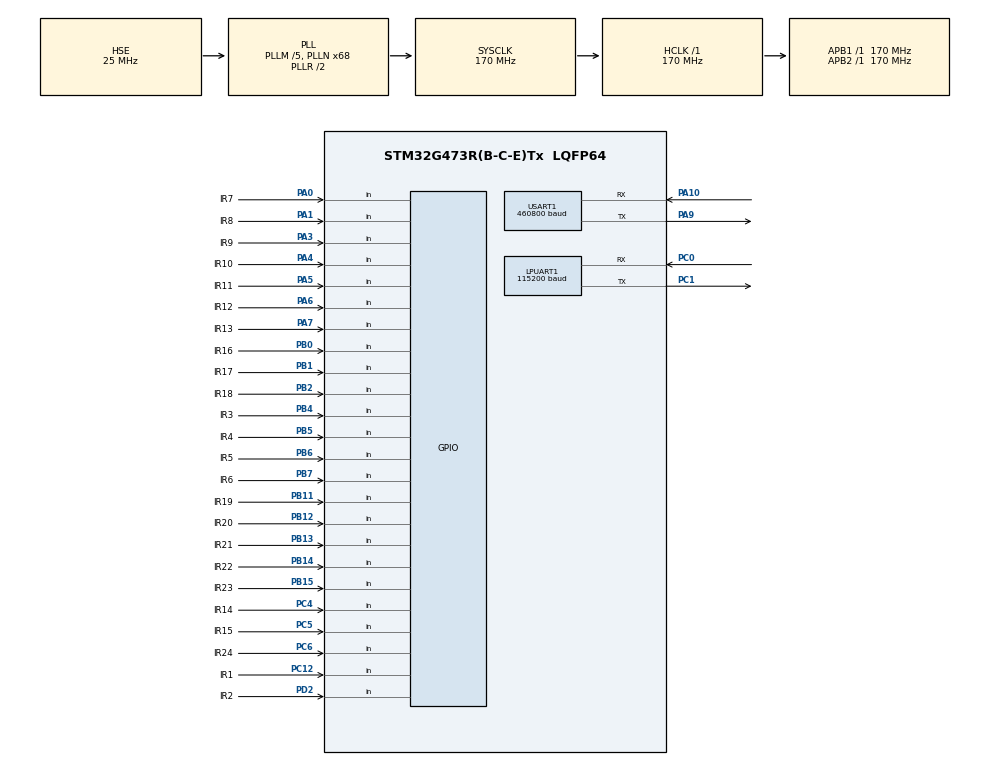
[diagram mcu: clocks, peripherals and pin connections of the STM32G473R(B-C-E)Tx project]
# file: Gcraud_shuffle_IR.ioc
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LPUART1.BaudRate=115200
Mcu.Family=STM32G4
Mcu.Name=STM32G473R(B-C-E)Tx
Mcu.Package=LQFP64
NVIC.LPUART1_IRQn=true\:0\:0\:false\:false\:true\:true\:true\:true
NVIC.PriorityGroup=NVIC_PRIORITYGROUP_4
NVIC.USART1_IRQn=true\:0\:0\:false\:false\:true\:true\:true\:true
PA0.GPIO_Label=IR7
PA0.Signal=GPIO_Input
PA1.GPIO_Label=IR8
PA1.Signal=GPIO_Input
PA10.Mode=Asynchronous
PA10.Signal=USART1_RX
PA13.Mode=Serial_Wire
PA13.Signal=SYS_JTMS-SWDIO
PA14.Mode=Serial_Wire
PA14.Signal=SYS_JTCK-SWCLK
PA3.GPIO_Label=IR9
PA3.Signal=GPIO_Input
PA4.GPIO_Label=IR10
PA4.Signal=GPIO_Input
PA5.GPIO_Label=IR11
PA5.Signal=GPIO_Input
PA6.GPIO_Label=IR12
PA6.Signal=GPIO_Input
PA7.GPIO_Label=IR13
PA7.Signal=GPIO_Input
PA9.Mode=Asynchronous
PA9.Signal=USART1_TX
PB0.GPIO_Label=IR16
PB0.Signal=GPIO_Input
PB1.GPIO_Label=IR17
PB1.Signal=GPIO_Input
PB11.GPIO_Label=IR19
PB11.Signal=GPIO_Input
PB12.GPIO_Label=IR20
PB12.Signal=GPIO_Input
PB13.GPIO_Label=IR21
PB13.Signal=GPIO_Input
PB14.GPIO_Label=IR22
PB14.Signal=GPIO_Input
PB15.GPIO_Label=IR23
PB15.Signal=GPIO_Input
PB2.GPIO_Label=IR18
PB2.Signal=GPIO_Input
PB3.Signal=SYS_JTDO-SWO
PB4.GPIO_Label=IR3
PB4.Signal=GPIO_Input
PB5.GPIO_Label=IR4
PB5.Signal=GPIO_Input
PB6.GPIO_Label=IR5
PB6.Signal=GPIO_Input
PB7.GPIO_Label=IR6
PB7.Signal=GPIO_Input
PC0.Mode=Asynchronous
PC0.Signal=LPUART1_RX
PC1.Mode=Asynchronous
PC1.Signal=LPUART1_TX
PC12.GPIO_Label=IR1
PC12.Signal=GPIO_Input
PC4.GPIO_Label=IR14
PC4.Signal=GPIO_Input
PC5.GPIO_Label=IR15
PC5.Signal=GPIO_Input
PC6.GPIO_Label=IR24
PC6.Signal=GPIO_Input
PD2.GPIO_Label=IR2
PD2.Signal=GPIO_Input
PF0-OSC_IN.Mode=HSE-External-Oscillator
PF0-OSC_IN.Signal=RCC_OSC_IN
PF1-OSC_OUT.Mode=HSE-External-Oscillator
PF1-OSC_OUT.Signal=RCC_OSC_OUT
ProjectManager.HeapSize=0x200
ProjectManager.StackSize=0x400
ProjectManager.TargetToolchain=STM32CubeIDE
RCC.ADC12Freq_Value=170000000
RCC.ADC345Freq_Value=170000000
RCC.AHBFreq_Value=170000000
RCC.APB1Freq_Value=170000000
RCC.APB1TimFreq_Value=170000000
RCC.APB2Freq_Value=170000000
RCC.APB2TimFreq_Value=170000000
RCC.CortexFreq_Value=170000000
RCC.EXTERNAL_CLOCK_VALUE=12288000
RCC.HCLKFreq_Value=170000000
RCC.HSE_VALUE=25000000
RCC.HSI48_VALUE=48000000
RCC.HSI_VALUE=16000000
RCC.LSE_VALUE=32768
RCC.PLLM=RCC_PLLM_DIV5
RCC.PLLN=68
RCC.PLLSourceVirtual=RCC_PLLSOURCE_HSE
RCC.SYSCLKFreq_VALUE=170000000
RCC.SYSCLKSource=RCC_SYSCLKSOURCE_PLLCLK
RCC.USBFreq_Value=170000000
RCC.VCOOutputFreq_Value=340000000
USART1.BaudRate=460800
USART1.VirtualMode-Asynchronous=VM_ASYNC
VP_SYS_VS_DBSignals.Mode=DisableDeadBatterySignals
board=custom

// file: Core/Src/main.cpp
/* USER CODE BEGIN Header */
/**
  ******************************************************************************
  * @file           : main.c
  * @brief          : Main program body
  ******************************************************************************
  * @attention
  *
  * Copyright (c) 2025 STMicroelectronics.
  * All rights reserved.
  *
  * This software is licensed under terms that can be found in the LICENSE file
  * in the root directory of this software component.
  * If no LICENSE file comes with this software, it is provided AS-IS.
  *
  ******************************************************************************
  */
/* USER CODE END Header */
#include "main.h"

/* USER CODE BEGIN Includes */
#include "app.hpp"
/* USER CODE END Includes */

UART_HandleTypeDef hlpuart1;
UART_HandleTypeDef huart1;

void SystemClock_Config(void);
static void MX_GPIO_Init(void);
static void MX_LPUART1_UART_Init(void);
static void MX_USART1_UART_Init(void);

/* USER CODE BEGIN 0 */
//bool flag_uart = 1;
//
uint8_t Sendtheta = 0;
uint8_t Send_R = 0;
uint8_t SEnd = 1;
//uint8_t Send_Data;
enum{IR_THETAreq, IR_CLOSENESSreq, LINE_Xreq, LINE_Yreq};

uint8_t Received_Buff[1];

void HAL_UART_RxCpltCallback(UART_HandleTypeDef *huart){

//	HAL_UART_Transmit(&huart1, &Send_Data, 1, 10);
	HAL_UART_Transmit(&huart1, &Sendtheta, 1, 10); 			//IR_CLOSENESSreq is the channel of R(:closeness in main).
	HAL_UART_Transmit(&huart1, &Send_R, 1, 10);

	HAL_UART_Receive_IT(&huart1, Received_Buff, 1);

}
/* USER CODE END 0 */

int main(void)
{

  /* MCU Configuration--------------------------------------------------------*/

  /* Reset of all peripherals, Initializes the Flash interface and the Systick. */
  HAL_Init();

  /* Configure the system clock */
  SystemClock_Config();

  /* Initialize all configured peripherals */
  MX_GPIO_Init();
  MX_LPUART1_UART_Init();
  MX_USART1_UART_Init();
  /* USER CODE BEGIN 2 */
  HAL_UART_Receive_IT(&huart1, Received_Buff, 1);
  app(&hlpuart1,&huart1, /*&Send_Data,*/ &Sendtheta, &Send_R);
  /* USER CODE END 2 */

  /* Infinite loop */
  while (1)
  {

  }
}

void SystemClock_Config(void)
{
  RCC_OscInitTypeDef RCC_OscInitStruct = {0};
  RCC_ClkInitTypeDef RCC_ClkInitStruct = {0};

  /** Configure the main internal regulator output voltage
  */
  HAL_PWREx_ControlVoltageScaling(PWR_REGULATOR_VOLTAGE_SCALE1_BOOST);

  /** Initializes the RCC Oscillators according to the specified parameters
  * in the RCC_OscInitTypeDef structure.
  */
  RCC_OscInitStruct.OscillatorType = RCC_OSCILLATORTYPE_HSE;
  RCC_OscInitStruct.HSEState = RCC_HSE_ON;
  RCC_OscInitStruct.PLL.PLLState = RCC_PLL_ON;
  RCC_OscInitStruct.PLL.PLLSource = RCC_PLLSOURCE_HSE;
  RCC_OscInitStruct.PLL.PLLM = RCC_PLLM_DIV5;
  RCC_OscInitStruct.PLL.PLLN = 68;
  RCC_OscInitStruct.PLL.PLLP = RCC_PLLP_DIV2;
  RCC_OscInitStruct.PLL.PLLQ = RCC_PLLQ_DIV2;
  RCC_OscInitStruct.PLL.PLLR = RCC_PLLR_DIV2;
  if (HAL_RCC_OscConfig(&RCC_OscInitStruct) != HAL_OK)
  {
    Error_Handler();
  }

  /** Initializes the CPU, AHB and APB buses clocks
  */
  RCC_ClkInitStruct.ClockType = RCC_CLOCKTYPE_HCLK|RCC_CLOCKTYPE_SYSCLK
                              |RCC_CLOCKTYPE_PCLK1|RCC_CLOCKTYPE_PCLK2;
  RCC_ClkInitStruct.SYSCLKSource = RCC_SYSCLKSOURCE_PLLCLK;
  RCC_ClkInitStruct.AHBCLKDivider = RCC_SYSCLK_DIV1;
  RCC_ClkInitStruct.APB1CLKDivider = RCC_HCLK_DIV1;
  RCC_ClkInitStruct.APB2CLKDivider = RCC_HCLK_DIV1;

  if (HAL_RCC_ClockConfig(&RCC_ClkInitStruct, FLASH_LATENCY_4) != HAL_OK)
  {
    Error_Handler();
  }
}

static void MX_LPUART1_UART_Init(void)
{

  hlpuart1.Instance = LPUART1;
  hlpuart1.Init.BaudRate = 115200;
  hlpuart1.Init.WordLength = UART_WORDLENGTH_8B;
  hlpuart1.Init.StopBits = UART_STOPBITS_1;
  hlpuart1.Init.Parity = UART_PARITY_NONE;
  hlpuart1.Init.Mode = UART_MODE_TX_RX;
  hlpuart1.Init.HwFlowCtl = UART_HWCONTROL_NONE;
  hlpuart1.Init.OneBitSampling = UART_ONE_BIT_SAMPLE_DISABLE;
  hlpuart1.Init.ClockPrescaler = UART_PRESCALER_DIV1;
  hlpuart1.AdvancedInit.AdvFeatureInit = UART_ADVFEATURE_NO_INIT;
  if (HAL_UART_Init(&hlpuart1) != HAL_OK)
  {
    Error_Handler();
  }
  if (HAL_UARTEx_SetTxFifoThreshold(&hlpuart1, UART_TXFIFO_THRESHOLD_1_8) != HAL_OK)
  {
    Error_Handler();
  }
  if (HAL_UARTEx_SetRxFifoThreshold(&hlpuart1, UART_RXFIFO_THRESHOLD_1_8) != HAL_OK)
  {
    Error_Handler();
  }
  if (HAL_UARTEx_DisableFifoMode(&hlpuart1) != HAL_OK)
  {
    Error_Handler();
  }

}

static void MX_USART1_UART_Init(void)
{

  huart1.Instance = USART1;
  huart1.Init.BaudRate = 460800;
  huart1.Init.WordLength = UART_WORDLENGTH_8B;
  huart1.Init.StopBits = UART_STOPBITS_1;
  huart1.Init.Parity = UART_PARITY_NONE;
  huart1.Init.Mode = UART_MODE_TX_RX;
  huart1.Init.HwFlowCtl = UART_HWCONTROL_NONE;
  huart1.Init.OverSampling = UART_OVERSAMPLING_16;
  huart1.Init.OneBitSampling = UART_ONE_BIT_SAMPLE_DISABLE;
  huart1.Init.ClockPrescaler = UART_PRESCALER_DIV1;
  huart1.AdvancedInit.AdvFeatureInit = UART_ADVFEATURE_NO_INIT;
  if (HAL_UART_Init(&huart1) != HAL_OK)
  {
    Error_Handler();
  }
  if (HAL_UARTEx_SetTxFifoThreshold(&huart1, UART_TXFIFO_THRESHOLD_1_8) != HAL_OK)
  {
    Error_Handler();
  }
  if (HAL_UARTEx_SetRxFifoThreshold(&huart1, UART_RXFIFO_THRESHOLD_1_8) != HAL_OK)
  {
    Error_Handler();
  }
  if (HAL_UARTEx_DisableFifoMode(&huart1) != HAL_OK)
  {
    Error_Handler();
  }

}

static void MX_GPIO_Init(void)
{
  GPIO_InitTypeDef GPIO_InitStruct = {0};

  /* GPIO Ports Clock Enable */
  __HAL_RCC_GPIOF_CLK_ENABLE();
  __HAL_RCC_GPIOC_CLK_ENABLE();
  __HAL_RCC_GPIOA_CLK_ENABLE();
  __HAL_RCC_GPIOB_CLK_ENABLE();
  __HAL_RCC_GPIOD_CLK_ENABLE();

  /*Configure GPIO pins : IR7_Pin IR8_Pin IR9_Pin IR10_Pin
                           IR11_Pin IR12_Pin IR13_Pin */
  GPIO_InitStruct.Pin = IR7_Pin|IR8_Pin|IR9_Pin|IR10_Pin
                          |IR11_Pin|IR12_Pin|IR13_Pin;
  GPIO_InitStruct.Mode = GPIO_MODE_INPUT;
  GPIO_InitStruct.Pull = GPIO_NOPULL;
  HAL_GPIO_Init(GPIOA, &GPIO_InitStruct);

  /*Configure GPIO pins : IR14_Pin IR15_Pin IR24_Pin IR1_Pin */
  GPIO_InitStruct.Pin = IR14_Pin|IR15_Pin|IR24_Pin|IR1_Pin;
  GPIO_InitStruct.Mode = GPIO_MODE_INPUT;
  GPIO_InitStruct.Pull = GPIO_NOPULL;
  HAL_GPIO_Init(GPIOC, &GPIO_InitStruct);

  /*Configure GPIO pins : IR16_Pin IR17_Pin IR18_Pin IR19_Pin
                           IR20_Pin IR21_Pin IR22_Pin IR23_Pin
                           IR3_Pin IR4_Pin IR5_Pin IR6_Pin */
  GPIO_InitStruct.Pin = IR16_Pin|IR17_Pin|IR18_Pin|IR19_Pin
                          |IR20_Pin|IR21_Pin|IR22_Pin|IR23_Pin
                          |IR3_Pin|IR4_Pin|IR5_Pin|IR6_Pin;
  GPIO_InitStruct.Mode = GPIO_MODE_INPUT;
  GPIO_InitStruct.Pull = GPIO_NOPULL;
  HAL_GPIO_Init(GPIOB, &GPIO_InitStruct);

  /*Configure GPIO pin : IR2_Pin */
  GPIO_InitStruct.Pin = IR2_Pin;
  GPIO_InitStruct.Mode = GPIO_MODE_INPUT;
  GPIO_InitStruct.Pull = GPIO_NOPULL;
  HAL_GPIO_Init(IR2_GPIO_Port, &GPIO_InitStruct);

}

void Error_Handler(void)
{
  __disable_irq();
  while (1)
  {
  }
}
